# M344 register map
File version: 2.0.2.6
Registers are 32-bit, read-write, reset 0x0 unless marked. A register's access mark holds for its fields unless they carry their own. Offsets are from the block's base; [hi:lo] are bit positions; {n}, {i} and the like mark numbered series.

## TSPI3 — Serial Interface (TSPI)
Base 0x4009B000
Same registers: TSPI4 0x4009C000, TSPI1 0x40299000, TSPI2 0x4039A000, TSPI0 0x40498000
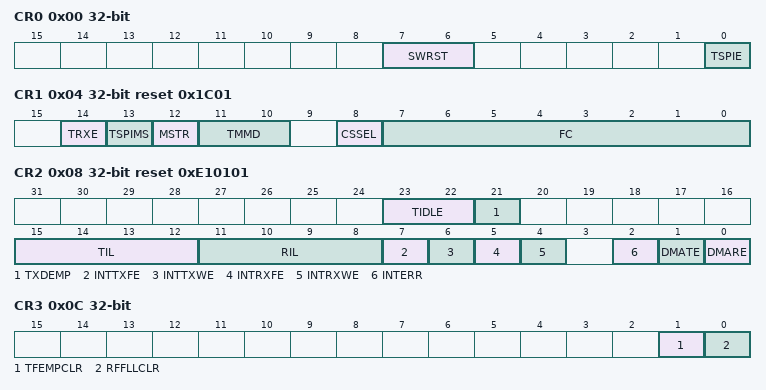
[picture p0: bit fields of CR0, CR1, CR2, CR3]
0x00 CR0 — TSPI Control Register 0
  [7:6] SWRST wo, [0] TSPIE
0x04 CR1 reset 0x1C01 — TSPI Control Register 1
  [14] TRXE, [13] TSPIMS, [12] MSTR, [11:10] TMMD, [8] CSSEL, [7:0] FC
0x08 CR2 reset 0xE10101 — TSPI Control Register 2
  [23:22] TIDLE, [21] TXDEMP, [15:12] TIL, [11:8] RIL, [7] INTTXFE, [6] INTTXWE, [5] INTRXFE, [4] INTRXWE, [2] INTERR, [1] DMATE, [0] DMARE
0x0C CR3 — TSPI Control Register 3
  [1] TFEMPCLR wo, [0] RFFLLCLR wo
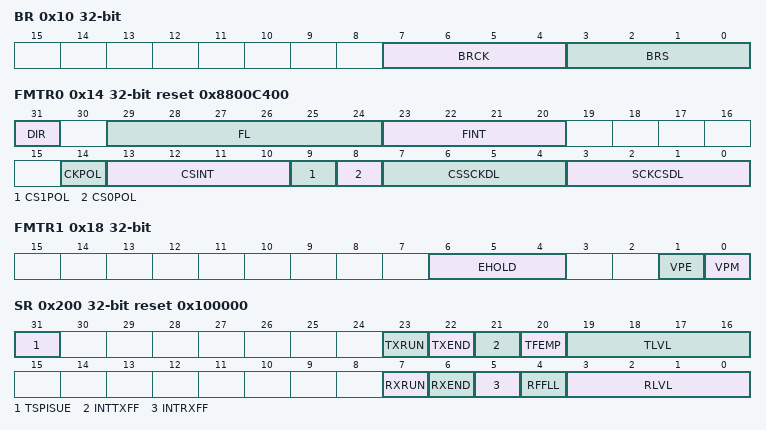
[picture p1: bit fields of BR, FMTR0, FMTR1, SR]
0x10 BR — TSPI Baud Rate Generator Control Register
  [7:4] BRCK, [3:0] BRS
0x14 FMTR0 reset 0x8800C400 — TSPI Format Control Register 0
  [31] DIR, [29:24] FL, [23:20] FINT, [14] CKPOL, [13:10] CSINT, [9] CS1POL, [8] CS0POL, [7:4] CSSCKDL, [3:0] SCKCSDL
0x18 FMTR1 — TSPI Format Control Register 1
  [6:4] EHOLD, [1] VPE, [0] VPM
0x100 DR — TSPI Data Register
  [31:0] TSPIDR
0x200 SR reset 0x100000 — TSPI Status Register
  [31] TSPISUE ro, [23] TXRUN ro, [22] TXEND, [21] INTTXFF, [20] TFEMP ro, [19:16] TLVL ro, [7] RXRUN ro, [6] RXEND, [5] INTRXFF, [4] RFFLL ro, [3:0] RLVL ro
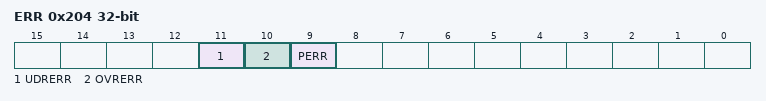
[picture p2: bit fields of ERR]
0x204 ERR — TSPI Parity Error Flag Register
  [11] UDRERR, [10] OVRERR, [9] PERR

## PA — Port A
Base 0x400C0000
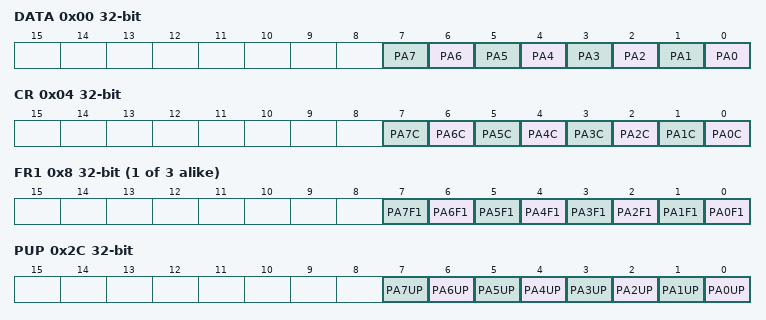
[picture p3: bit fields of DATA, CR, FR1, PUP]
0x00 DATA — Port A Data Register
  [n] PA{n} (n=0..7)
0x04 CR — Port A Output Control Register
  [n] PA{n}C (n=0..7)
{0x4+4i} FR{i} (i=1..3) — Port A Function Register {i}
  [n] PA{n}F{i} (n=0..7)
0x2C PUP — Port A Pull-up Control Register
  [n] PA{n}UP (n=0..7)
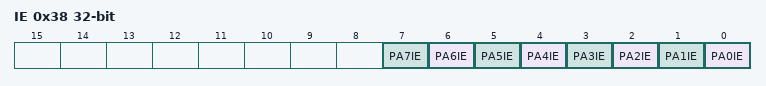
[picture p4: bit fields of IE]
0x38 IE — Port A Input Control Register
  [n] PA{n}IE (n=0..7)

## PB — Port B
Base 0x400C0100
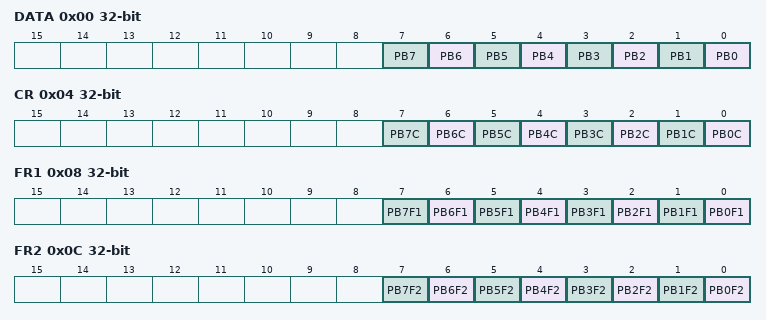
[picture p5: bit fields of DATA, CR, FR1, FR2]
0x00 DATA — Port B Data Register
  [n] PB{n} (n=0..7)
0x04 CR — Port B Output Control Register
  [n] PB{n}C (n=0..7)
0x08 FR1 — Port B Function Register 1
  [n] PB{n}F1 (n=0..7)
0x0C FR2 — Port B Function Register 2
  [n] PB{n}F2 (n=0..7)
0x10 FR3 — Port B Function Register 3
  [6] PB6F3
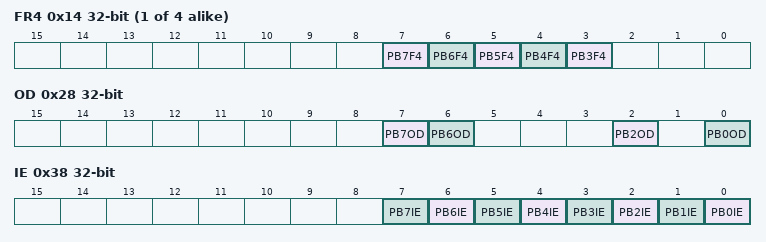
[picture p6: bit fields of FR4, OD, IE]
{0x4+4i} FR{i} (i=4..7) — Port B Function Register {i}
  [n] PB{n}F{i} (n=3..7)
0x28 OD — Port B Open Drain Control Register
  [7] PB7OD, [6] PB6OD, [2] PB2OD, [0] PB0OD
0x38 IE — Port B Input Control Register
  [n] PB{n}IE (n=0..7)

## PC — Port C
Base 0x400C0200
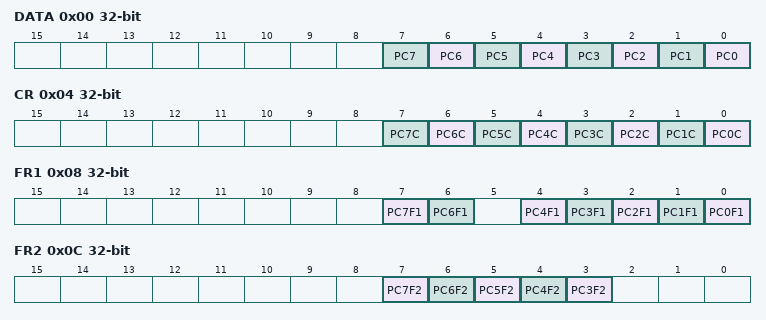
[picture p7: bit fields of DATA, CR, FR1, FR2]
0x00 DATA — Port C Data Register
  [n] PC{n} (n=0..7)
0x04 CR — Port C Output Control Register
  [n] PC{n}C (n=0..7)
0x08 FR1 — Port C Function Register 1
  [7] PC7F1, [6] PC6F1, [n] PC{n}F1 (n=0..4)
0x0C FR2 — Port C Function Register 2
  [n] PC{n}F2 (n=3..7)
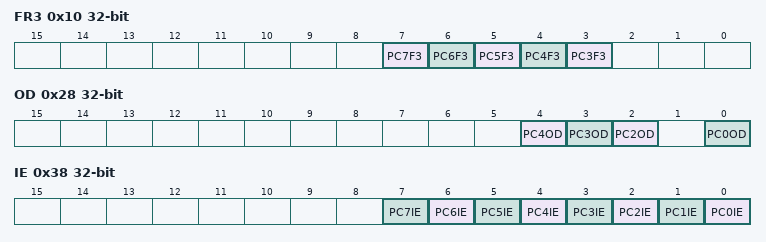
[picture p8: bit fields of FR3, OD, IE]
0x10 FR3 — Port C Function Register 3
  [n] PC{n}F3 (n=3..7)
0x28 OD — Port C Open Drain Control Register
  [4] PC4OD, [3] PC3OD, [2] PC2OD, [0] PC0OD
0x38 IE — Port C Input Control Register
  [n] PC{n}IE (n=0..7)

## PD — Port D
Base 0x400C0300
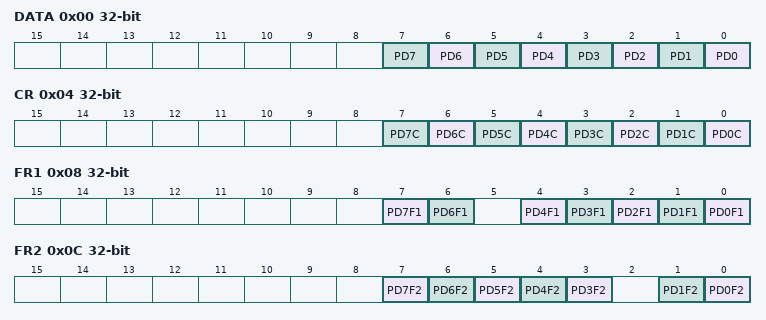
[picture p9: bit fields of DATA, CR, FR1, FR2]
0x00 DATA — Port D Data Register
  [n] PD{n} (n=0..7)
0x04 CR — Port D Output Control Register
  [n] PD{n}C (n=0..7)
0x08 FR1 — Port D Function Register 1
  [7] PD7F1, [6] PD6F1, [n] PD{n}F1 (n=0..4)
0x0C FR2 — Port D Function Register 2
  [n] PD{n}F2 (n=3..7), [1] PD1F2, [0] PD0F2
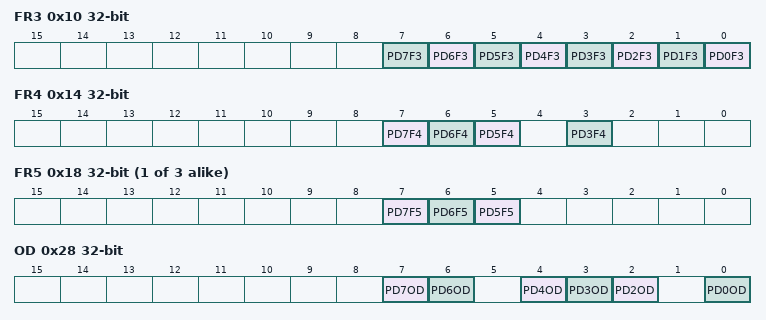
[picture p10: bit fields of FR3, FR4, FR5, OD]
0x10 FR3 — Port D Function Register 3
  [n] PD{n}F3 (n=0..7)
0x14 FR4 — Port D Function Register 4
  [7] PD7F4, [6] PD6F4, [5] PD5F4, [3] PD3F4
{0x4+4i} FR{i} (i=5..7) — Port D Function Register {i}
  [7] PD7F{i}, [6] PD6F{i}, [5] PD5F{i}
0x28 OD — Port D Open Drain Control Register
  [7] PD7OD, [6] PD6OD, [4] PD4OD, [3] PD3OD, [2] PD2OD, [0] PD0OD
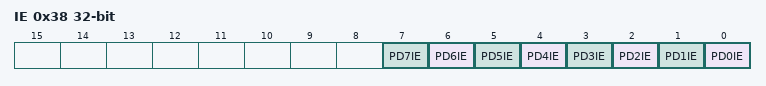
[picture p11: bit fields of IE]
0x38 IE — Port D Input Control Register
  [n] PD{n}IE (n=0..7)

## PE — Port E
Base 0x400C0400
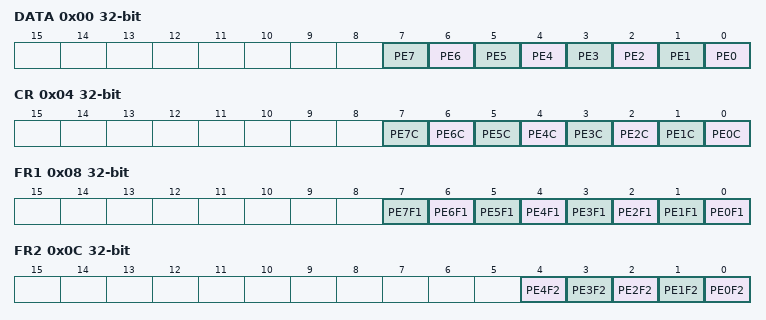
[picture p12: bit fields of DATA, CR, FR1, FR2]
0x00 DATA — Port E Data Register
  [n] PE{n} (n=0..7)
0x04 CR — Port E Output Control Register
  [n] PE{n}C (n=0..7)
0x08 FR1 — Port E Function Register 1
  [n] PE{n}F1 (n=0..7)
0x0C FR2 — Port E Function Register 2
  [n] PE{n}F2 (n=0..4)
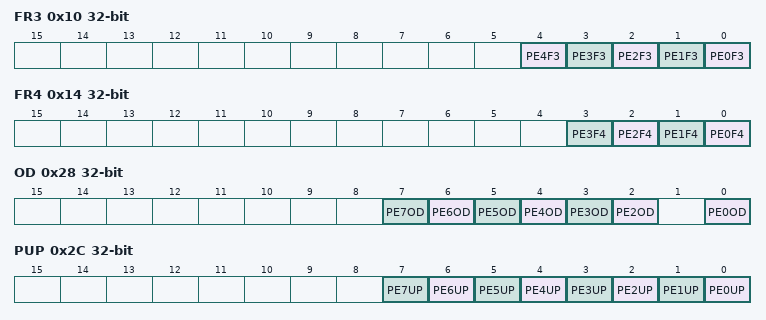
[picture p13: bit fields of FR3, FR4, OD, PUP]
0x10 FR3 — Port E Function Register 3
  [n] PE{n}F3 (n=0..4)
0x14 FR4 — Port E Function Register 4
  [n] PE{n}F4 (n=0..3)
0x28 OD — Port E Open Drain Control Register
  [n] PE{n}OD (n=2..7), [0] PE0OD
0x2C PUP — Port E Pull-up Control Register
  [n] PE{n}UP (n=0..7)
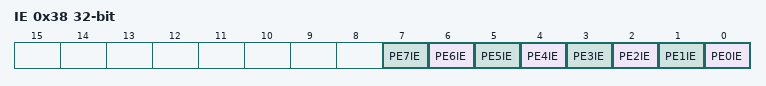
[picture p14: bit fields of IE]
0x38 IE — Port E Input Control Register
  [n] PE{n}IE (n=0..7)
